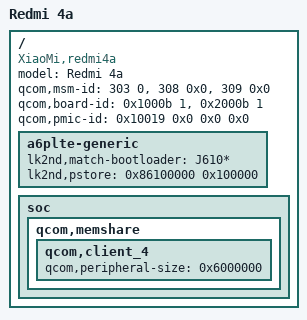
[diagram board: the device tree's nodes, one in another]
// SPDX-License-Identifier: GPL-2.0-only

/dts-v1/;

/include/ "msm8952.dtsi"

/ {
	// This is used by the bootloader to find the correct DTB
	model = "Redmi 4a";
	compatible = "XiaoMi,redmi4a", "qcom,msm8917", "lk2nd,device";
	
	qcom,msm-id = <303 0>, <308 0x0>, <309 0x0>;
	qcom,board-id= <0x1000b 1>, <0x2000b 1>;
	qcom,pmic-id = <0x10019 0x0 0x0 0x0>;

	a6plte-generic {
		
		lk2nd,match-bootloader = "J610*";
		lk2nd,pstore = <0x86100000 0x100000>;
	};

	// Bootloader won't continue if it can't delete some nodes from below
	soc {
		#address-cells = <1>;
		#size-cells = <1>;
		ranges = <0x0 0x0 0x0 0xffffffff>;

		qcom,memshare {
			qcom,client_4 {
				qcom,peripheral-size = <0x6000000>;
			};
		};
	};

};
